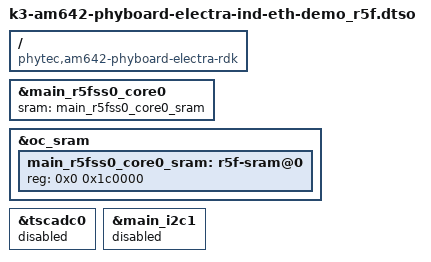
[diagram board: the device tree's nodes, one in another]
// SPDX-License-Identifier: GPL-2.0-only OR MIT
/*
 * Copyright (C) 2025 IBV - Echtzeit- und Embedded GmbH & Co. KG
 */

/dts-v1/;
/plugin/;

/ {
	compatible = "phytec,am642-phyboard-electra-rdk";
};

/* MSRAM for R5F */
&main_r5fss0_core0 {
	sram = <&main_r5fss0_core0_sram>;
};

&oc_sram {
	#address-cells = <1>;
	#size-cells = <1>;

	main_r5fss0_core0_sram: r5f-sram@0 {
		reg = <0x0 0x1c0000>;
	};
};

/* disable ADC */
&tscadc0 {
	status = "disabled";
};

&main_i2c1 {
	status = "disabled";
};
